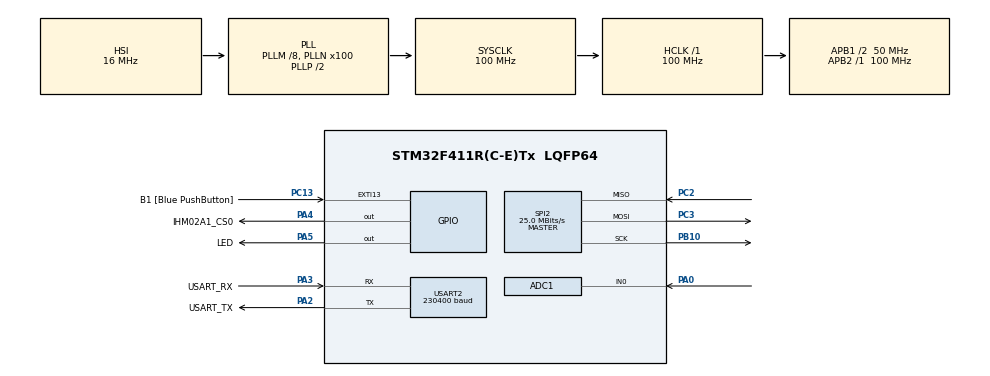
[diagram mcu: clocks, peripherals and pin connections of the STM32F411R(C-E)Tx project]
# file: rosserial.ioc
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ADC1.Channel-0\#ChannelRegularConversion=ADC_CHANNEL_0
ADC1.NbrOfConversionFlag=1
ADC1.Rank-0\#ChannelRegularConversion=1
ADC1.SamplingTime-0\#ChannelRegularConversion=ADC_SAMPLETIME_3CYCLES
ADC1.master=1
Dma.Request0=USART2_RX
Dma.Request1=USART2_TX
Dma.USART2_RX.0.Direction=DMA_PERIPH_TO_MEMORY
Dma.USART2_RX.0.FIFOMode=DMA_FIFOMODE_DISABLE
Dma.USART2_RX.0.Instance=DMA1_Stream7
Dma.USART2_RX.0.MemDataAlignment=DMA_MDATAALIGN_BYTE
Dma.USART2_RX.0.MemInc=DMA_MINC_ENABLE
Dma.USART2_RX.0.Mode=DMA_CIRCULAR
Dma.USART2_RX.0.PeriphDataAlignment=DMA_PDATAALIGN_BYTE
Dma.USART2_RX.0.PeriphInc=DMA_PINC_DISABLE
Dma.USART2_RX.0.Priority=DMA_PRIORITY_HIGH
Dma.USART2_TX.1.Direction=DMA_MEMORY_TO_PERIPH
Dma.USART2_TX.1.FIFOMode=DMA_FIFOMODE_DISABLE
Dma.USART2_TX.1.Instance=DMA1_Stream6
Dma.USART2_TX.1.MemDataAlignment=DMA_MDATAALIGN_BYTE
Dma.USART2_TX.1.MemInc=DMA_MINC_ENABLE
Dma.USART2_TX.1.Mode=DMA_NORMAL
Dma.USART2_TX.1.PeriphDataAlignment=DMA_PDATAALIGN_BYTE
Dma.USART2_TX.1.PeriphInc=DMA_PINC_DISABLE
Dma.USART2_TX.1.Priority=DMA_PRIORITY_HIGH
Mcu.Family=STM32F4
Mcu.Name=STM32F411R(C-E)Tx
Mcu.Package=LQFP64
NVIC.DMA1_Stream6_IRQn=true\:0\:0\:false\:false\:true\:false
NVIC.DMA1_Stream7_IRQn=true\:0\:0\:false\:false\:true\:false
NVIC.PriorityGroup=NVIC_PRIORITYGROUP_4
NVIC.TIM1_UP_TIM10_IRQn=true\:0\:0\:false\:false\:true\:false
NVIC.TIM3_IRQn=true\:0\:0\:false\:false\:true\:true
NVIC.TimeBase=TIM1_UP_TIM10_IRQn
NVIC.TimeBaseIP=TIM1
NVIC.USART2_IRQn=true\:0\:0\:false\:false\:true\:true
PA0-WKUP.Signal=ADCx_IN0
PA13.GPIO_Label=TMS
PA13.Mode=Serial_Wire
PA13.Signal=SYS_JTMS-SWDIO
PA14.GPIO_Label=TCK
PA14.Mode=Serial_Wire
PA14.Signal=SYS_JTCK-SWCLK
PA2.GPIO_Label=USART_TX
PA2.Mode=Asynchronous
PA2.Signal=USART2_TX
PA3.GPIO_Label=USART_RX
PA3.Mode=Asynchronous
PA3.Signal=USART2_RX
PA4.GPIO_Label=IHM02A1_CS0
PA4.GPIO_Speed=GPIO_SPEED_FREQ_HIGH
PA4.Signal=GPIO_Output
PA5.GPIO_Label=LED
PA5.Signal=GPIO_Output
PB10.Mode=Full_Duplex_Master
PB10.Signal=SPI2_SCK
PB3.GPIO_Label=SWO
PB3.Signal=SYS_JTDO-SWO
PC13-ANTI_TAMP.GPIO_Label=B1 [Blue PushButton]
PC13-ANTI_TAMP.GPIO_ModeDefaultEXTI=GPIO_MODE_IT_FALLING
PC13-ANTI_TAMP.Signal=GPXTI13
PC14-OSC32_IN.Mode=LSE-External-Oscillator
PC14-OSC32_IN.Signal=RCC_OSC32_IN
PC15-OSC32_OUT.Mode=LSE-External-Oscillator
PC15-OSC32_OUT.Signal=RCC_OSC32_OUT
PC2.Mode=Full_Duplex_Master
PC2.Signal=SPI2_MISO
PC3.Mode=Full_Duplex_Master
PC3.Signal=SPI2_MOSI
PH0\ -\ OSC_IN.Mode=HSE-External-Clock-Source
PH0\ -\ OSC_IN.Signal=RCC_OSC_IN
PH1\ -\ OSC_OUT.Mode=HSE-External-Clock-Source
PH1\ -\ OSC_OUT.Signal=RCC_OSC_OUT
ProjectManager.HeapSize=0x200
ProjectManager.StackSize=0x400
ProjectManager.TargetToolchain=SW4STM32
RCC.48MHZClocksFreq_Value=50000000
RCC.AHBFreq_Value=100000000
RCC.APB1CLKDivider=RCC_HCLK_DIV2
RCC.APB1Freq_Value=50000000
RCC.APB1TimFreq_Value=100000000
RCC.APB2Freq_Value=100000000
RCC.APB2TimFreq_Value=100000000
RCC.CortexFreq_Value=100000000
RCC.FLatency-AdvancedSettings=FLASH_LATENCY_3
RCC.HCLKFreq_Value=100000000
RCC.HSE_VALUE=8000000
RCC.HSI_VALUE=16000000
RCC.PLLM=8
RCC.PLLN=100
RCC.SYSCLKFreq_VALUE=100000000
RCC.SYSCLKSource=RCC_SYSCLKSOURCE_PLLCLK
RCC.VCOOutputFreq_Value=200000000
SH.ADCx_IN0.0=ADC1_IN0,IN0
SPI2.CalculateBaudRate=25.0 MBits/s
SPI2.Direction=SPI_DIRECTION_2LINES
SPI2.Mode=SPI_MODE_MASTER
SPI2.VirtualType=VM_MASTER
TIM2.Period=0xffffffff
TIM2.Prescaler=64000-1
TIM3.Period=2000-1
TIM3.Prescaler=50-1
USART2.BaudRate=230400
USART2.VirtualMode=VM_ASYNC
VP_SYS_VS_tim1.Mode=TIM1
VP_TIM2_VS_ClockSourceINT.Mode=Internal
VP_TIM3_VS_ClockSourceINT.Mode=Internal
board=NUCLEO-F411RE

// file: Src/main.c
/**
  ******************************************************************************
  * @file           : main.c
  * @brief          : Main program body
  ******************************************************************************
  ** This notice applies to any and all portions of this file
  * that are not between comment pairs USER CODE BEGIN and
  * USER CODE END. Other portions of this file, whether
  * inserted by the user or by software development tools
  * are owned by their respective copyright owners.
  *
  * COPYRIGHT(c) 2018 STMicroelectronics
  *
  * Redistribution and use in source and binary forms, with or without modification,
  * are permitted provided that the following conditions are met:
  *   1. Redistributions of source code must retain the above copyright notice,
  *      this list of conditions and the following disclaimer.
  *   2. Redistributions in binary form must reproduce the above copyright notice,
  *      this list of conditions and the following disclaimer in the documentation
  *      and/or other materials provided with the distribution.
  *   3. Neither the name of STMicroelectronics nor the names of its contributors
  *      may be used to endorse or promote products derived from this software
  *      without specific prior written permission.
  *
  * THIS SOFTWARE IS PROVIDED BY THE COPYRIGHT HOLDERS AND CONTRIBUTORS "AS IS"
  * AND ANY EXPRESS OR IMPLIED WARRANTIES, INCLUDING, BUT NOT LIMITED TO, THE
  * IMPLIED WARRANTIES OF MERCHANTABILITY AND FITNESS FOR A PARTICULAR PURPOSE ARE
  * DISCLAIMED. IN NO EVENT SHALL THE COPYRIGHT HOLDER OR CONTRIBUTORS BE LIABLE
  * FOR ANY DIRECT, INDIRECT, INCIDENTAL, SPECIAL, EXEMPLARY, OR CONSEQUENTIAL
  * DAMAGES (INCLUDING, BUT NOT LIMITED TO, PROCUREMENT OF SUBSTITUTE GOODS OR
  * SERVICES; LOSS OF USE, DATA, OR PROFITS; OR BUSINESS INTERRUPTION) HOWEVER
  * CAUSED AND ON ANY THEORY OF LIABILITY, WHETHER IN CONTRACT, STRICT LIABILITY,
  * OR TORT (INCLUDING NEGLIGENCE OR OTHERWISE) ARISING IN ANY WAY OUT OF THE USE
  * OF THIS SOFTWARE, EVEN IF ADVISED OF THE POSSIBILITY OF SUCH DAMAGE.
  *
  ******************************************************************************
  */
#include "main.h"
#include "stm32f4xx_hal.h"
#include "adc.h"
#include "dma.h"
#include "spi.h"
#include "tim.h"
#include "usart.h"
#include "gpio.h"

/* USER CODE BEGIN PV */
/* Private variables ---------------------------------------------------------*/

/* USER CODE END PV */

void SystemClock_Config(void);

/* USER CODE BEGIN PFP */
/* Private function prototypes -----------------------------------------------*/

/* USER CODE END PFP */

int main(void)
{

  /* MCU Configuration----------------------------------------------------------*/

  /* Reset of all peripherals, Initializes the Flash interface and the Systick. */
  HAL_Init();

  /* Configure the system clock */
  SystemClock_Config();

  /* Initialize all configured peripherals */
  MX_GPIO_Init();
  MX_DMA_Init();
  MX_USART2_UART_Init();
  MX_TIM2_Init();
  MX_ADC1_Init();
  MX_TIM3_Init();
  MX_SPI2_Init();
  /* USER CODE BEGIN 2 */
  BSP_Init();

  setup();
  /* USER CODE END 2 */

  /* Infinite loop */
  /* USER CODE BEGIN WHILE */
  while (1)
  {
	  loop();

  /* USER CODE END WHILE */

  }

}

void SystemClock_Config(void)
{

  RCC_OscInitTypeDef RCC_OscInitStruct;
  RCC_ClkInitTypeDef RCC_ClkInitStruct;

    /**Configure the main internal regulator output voltage
    */
  __HAL_RCC_PWR_CLK_ENABLE();

  __HAL_PWR_VOLTAGESCALING_CONFIG(PWR_REGULATOR_VOLTAGE_SCALE1);

    /**Initializes the CPU, AHB and APB busses clocks
    */
  RCC_OscInitStruct.OscillatorType = RCC_OSCILLATORTYPE_HSI;
  RCC_OscInitStruct.HSIState = RCC_HSI_ON;
  RCC_OscInitStruct.HSICalibrationValue = 16;
  RCC_OscInitStruct.PLL.PLLState = RCC_PLL_ON;
  RCC_OscInitStruct.PLL.PLLSource = RCC_PLLSOURCE_HSI;
  RCC_OscInitStruct.PLL.PLLM = 8;
  RCC_OscInitStruct.PLL.PLLN = 100;
  RCC_OscInitStruct.PLL.PLLP = RCC_PLLP_DIV2;
  RCC_OscInitStruct.PLL.PLLQ = 4;
  if (HAL_RCC_OscConfig(&RCC_OscInitStruct) != HAL_OK)
  {
    _Error_Handler(__FILE__, __LINE__);
  }

    /**Initializes the CPU, AHB and APB busses clocks
    */
  RCC_ClkInitStruct.ClockType = RCC_CLOCKTYPE_HCLK|RCC_CLOCKTYPE_SYSCLK
                              |RCC_CLOCKTYPE_PCLK1|RCC_CLOCKTYPE_PCLK2;
  RCC_ClkInitStruct.SYSCLKSource = RCC_SYSCLKSOURCE_PLLCLK;
  RCC_ClkInitStruct.AHBCLKDivider = RCC_SYSCLK_DIV1;
  RCC_ClkInitStruct.APB1CLKDivider = RCC_HCLK_DIV2;
  RCC_ClkInitStruct.APB2CLKDivider = RCC_HCLK_DIV1;

  if (HAL_RCC_ClockConfig(&RCC_ClkInitStruct, FLASH_LATENCY_3) != HAL_OK)
  {
    _Error_Handler(__FILE__, __LINE__);
  }

    /**Configure the Systick interrupt time
    */
  HAL_SYSTICK_Config(HAL_RCC_GetHCLKFreq()/1000);

    /**Configure the Systick
    */
  HAL_SYSTICK_CLKSourceConfig(SYSTICK_CLKSOURCE_HCLK);

  /* SysTick_IRQn interrupt configuration */
  HAL_NVIC_SetPriority(SysTick_IRQn, 0, 0);
}

void HAL_TIM_PeriodElapsedCallback(TIM_HandleTypeDef *htim)
{
  if (htim->Instance == TIM1) {
    HAL_IncTick();
  }
  /* USER CODE BEGIN Callback 1 */

  if (htim->Instance == TIM3) {
	  TIM3_PeriodElapsedCallback();
  }
  /* USER CODE END Callback 1 */
}

void _Error_Handler(char *file, int line)
{
  while(1)
  {
  }
}

/************************ (C) COPYRIGHT STMicroelectronics *****END OF FILE****/
